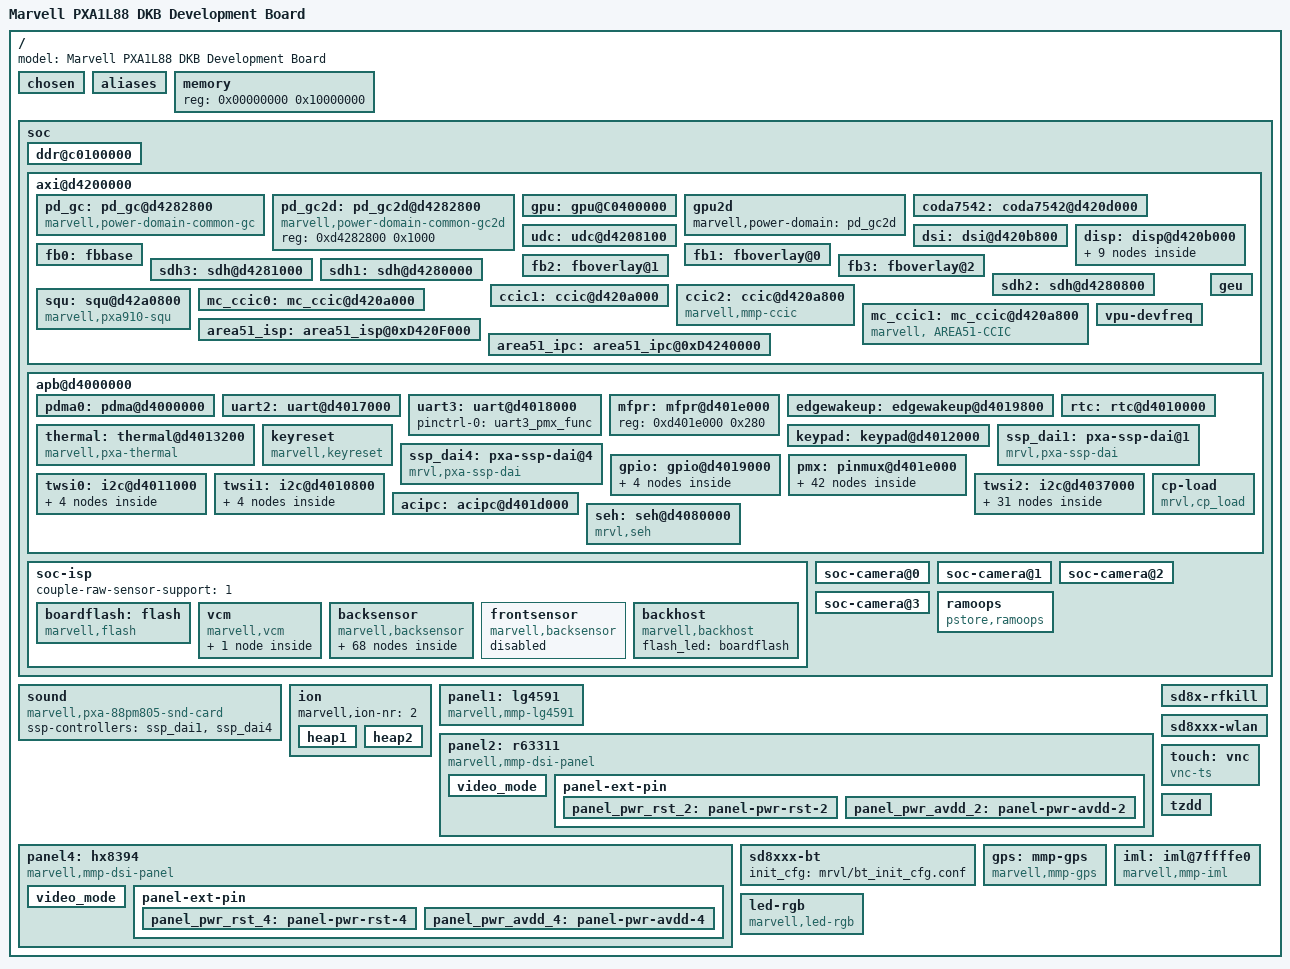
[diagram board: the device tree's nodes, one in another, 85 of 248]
/*
 *  Copyright (C) 2012 Marvell Technology Group Ltd.
 *  Author: Haojian Zhuang <haojian.zhuang@marvell.com>
 *
 *  This program is free software; you can redistribute it and/or modify
 *  it under the terms of the GNU General Public License version 2 as
 *  publishhed by the Free Software Foundation.
 */

/memreserve/ 0x09000000 0x01000000;	/* GPU (16MB)*/
/memreserve/ 0x08100000 0x00040000;	/* ramoops buffer (256KB) */
#include "pxa1088.dtsi"
#include "pxa1L88-pmic-config.dtsi"
#include <dt-bindings/mmc/pxa_sdhci.h>

/ {
	model = "Marvell PXA1L88 DKB Development Board";

	chosen {
		bootargs = "console=ttyS0,115200 root=/dev/nfs nfsroot=192.168.1.100:/nfsroot/ ip=192.168.1.101:192.168.1.100::255.255.255.0::eth0:on";
	};

	aliases {
		mmp-camera1 = &ccic2;
		area51-ccic1 = &mc_ccic1;
	};

	memory {
		reg = <0x00000000 0x10000000>;
	};

	soc {
		ddr@c0100000 {  /* DDR memory controller */
			status = "okay";
		};

		axi@d4200000 {	/* AXI */
			pd_gc: pd_gc@d4282800 {
				compatible = "marvell,power-domain-common-gc";
				reg = <0xd4282800 0x1000>;
				marvell,power-domain-parent = <&pd_gc2d>;
			};
			pd_gc2d: pd_gc2d@d4282800 {
				compatible = "marvell,power-domain-common-gc2d";
				reg = <0xd4282800 0x1000>;
			};
			gpu: gpu@C0400000 {
				marvell,power-domain = <&pd_gc>;
				marvell,gpu-mem-base = <0x09000000>;
				marvell,gpu-mem-size = <0x1000000>;
				status = "okay";
			};

			gpu2d {
				marvell,power-domain = <&pd_gc2d>;
				status = "okay";
			};

			coda7542: coda7542@d420d000 {
				marvell,sram-internal = <1>;
				marvell,nv21_support = <1>;
				status = "okay";
			};

			udc: udc@d4208100 {
				status = "okay";
			};

			dsi: dsi@d420b800 {
				marvell,phy-name = "mmp_dsi1";
				marvell,plat-path-name = "mmp_pnpath";
				marvell,dsi-lanes = <4>;
				marvell,burst-mode = <2>;
				marvell,hbp-en;
				status = "okay";
			};

			disp: disp@d420b000 {
				marvell,disp-name = "disp_name";
				marvell,path-num = <2>;
				marvell,master-path = "mmp_pnpath";
				marvell,slave-path = "mmp_tvpath";
				status = "okay";
				path1 {
					marvell,path-name = "mmp_pnpath";
					marvell,overlay-num = <2>;
					marvell,overlay-table = <0>, <1>;
					marvell,output-type = <1>;
					marvell,path-config = <0x10>;
					marvell,link-config = <0x1>;
					1080p {
						disp1_clksrc = "pll1_416m";
						dsipll_clksrc = "pll1_832m";
						pn_sclk_clksrc = "dsi_pll";
					};
					720p {
						disp1_clksrc = "pll1_416m";
						dsipll_clksrc = "pll3";
						pn_sclk_clksrc = "disp1";
					};
					qhd {
						disp1_clksrc = "pll1_416m";
						dsipll_clksrc = "pll3";
						pn_sclk_clksrc = "disp1";
					};
					WVGA {
						disp1_clksrc = "pll1_416m";
						dsipll_clksrc = "pll3";
						pn_sclk_clksrc = "dsi_pll";
					};
					disp_apmu {
						plat = <1>;
						apmu-reg = <0xd428284c>;
						clksrc-bit = <6>;
						parent1-clk-tbl = "disp1", "dsi_pll";
						parent2-clk-tbl = "pll1_416m", "pll1_624", "pll3", "pll2", "pll1_832m";
					};
				};
				path2 {
					marvell,path-name = "mmp_tvpath";
					marvell,overlay-num = <2>;
					marvell,overlay-table = <2>, <3>;
					marvell,output-type = <1>;
					marvell,path-config = <0x10>;
					marvell,link-config = <0x1>;
					1080p {
						disp1_clksrc = "pll1_416m";
						dsipll_clksrc = "pll1_832m";
						pn_sclk_clksrc = "dsi_pll";
					};
					720p {
						disp1_clksrc = "pll1_416m";
						dsipll_clksrc = "pll3";
						pn_sclk_clksrc = "disp1";
					};
				};
			};

			fb0: fbbase {
				marvell,fb-name = "mmp-fb";
				marvell,path-name = "mmp_pnpath";
				marvell,overlay-id = <1>;
				marvell,default-pixfmt = <0x109>;
				marvell,buffer-num = <3>;
				marvell,fb-mem = <0x17000000>;
				status = "okay";
			};

			fb1: fboverlay@0 {
				marvell,fb-name = "mmp-fb-overlay.0";
				marvell,path-name = "mmp_pnpath";
				marvell,overlay-id = <0>;
				status = "okay";
			};

			fb2: fboverlay@1 {
				marvell,fb-name = "mmp-fb-overlay.1";
				marvell,path-name = "mmp_tvpath";
				marvell,overlay-id = <3>;
				status = "okay";
			};

			fb3: fboverlay@2 {
				marvell,fb-name = "mmp-fb-overlay.2";
				marvell,path-name = "mmp_tvpath";
				marvell,overlay-id = <2>;
				status = "okay";
			};

			/* eMMC */
			sdh3: sdh@d4281000 {
				pinctrl-names = "default";
				pinctrl-0 = <&sdh3_pmx_func1 &sdh3_pmx_func2>;
				bus-width = <8>;
				non-removable;
				marvell,sdh-pm-runtime-en;
				marvell,sdh-quirks = <(
						SDHCI_QUIRK_BROKEN_ADMA |
						SDHCI_QUIRK_BROKEN_CARD_DETECTION
						)>;
				marvell,sdh-quirks2 = <(
						SDHCI_QUIRK2_BUS_CLK_GATE_ENABLED |
						SDHCI_QUIRK2_TIMEOUT_SHORT
						)>;
				marvell,sdh-host-caps = <(MMC_CAP_1_8V_DDR)>;
				marvell,sdh-host-caps2 = <(MMC_CAP2_DISABLE_BLK_ASYNC |
						MMC_CAP2_HS200_1_8V_SDR
						)>;
				marvell,sdh-flags = <(
						PXA_FLAG_SD_8_BIT_CAPABLE_SLOT |
						PXA_FLAG_ENABLE_CLOCK_GATING |
						PXA_FLAG_TX_SEL_BUS_CLK
					      )>;
/* prop "sdh-dtr-data": <timing preset_rate src_rate tx_delay rx_delay rx_clk_sel0 rx_clk_sel1 fclk_tune_level fclk_fix_en> */
				marvell,sdh-dtr-data = <PXA_MMC_TIMING_LEGACY PXA_SDH_DTR_26M PXA_SDH_DTR_104M 0 0 0 0 0 0>,
						<PXA_MMC_TIMING_MMC_HS PXA_SDH_DTR_52M PXA_SDH_DTR_104M 0 0 0 0 0 0>,
						<PXA_MMC_TIMING_UHS_DDR50 PXA_SDH_DTR_52M PXA_SDH_DTR_104M 0x6F 0 0 0 0 0>,
						<PXA_MMC_TIMING_MMC_HS200 PXA_SDH_DTR_208M PXA_SDH_DTR_208M 0 0 0 0 0 0>,
						<PXA_MMC_TIMING_MAX PXA_SDH_DTR_PS_NONE PXA_SDH_DTR_104M 0 0 0 0 0 0>;
				marvell,sdh-tuning-win-limit = <120>;
				marvell,sdh-dvfs-levels = <1 3>; /* tuning from dvfs level 1 to 3  */
				marvell,sdh-tuning-mode = <PXA_SDH_TUNING_DVFS>;

				status = "okay";
			};

			/* SD card */
			sdh1: sdh@d4280000 {
				pinctrl-names = "default";
				pinctrl-0 = <&sdh1_pmx_func1 &sdh1_pmx_func2 &sdh1_pmx_func3 &sdh1_pmx_func4>;
				vqmmc-supply	= <&ldo5>;
				vmmc-supply	= <&ldo4>;
				cd-gpios = <&gpio 91 0>;
				cd-inverted;
				bus-width = <4>;
				wp-inverted;
				marvell,sdh-pm-runtime-en;
				marvell,sdh-host-caps-disable = <(MMC_CAP_UHS_SDR104)>;
				marvell,sdh-quirks = <(
						SDHCI_QUIRK_INVERTED_WRITE_PROTECT |
						SDHCI_QUIRK_BROKEN_CARD_DETECTION
						)>;
				marvell,sdh-quirks2 = <(
						SDHCI_QUIRK2_BUS_CLK_GATE_ENABLED |
						SDHCI_QUIRK2_TIMEOUT_SHORT
						)>;
				marvell,sdh-flags = <(
						PXA_FLAG_TX_SEL_BUS_CLK |
						PXA_FLAG_ENABLE_CLOCK_GATING
					      )>;
/* prop "sdh-dtr-data": <timing preset_rate src_rate tx_delay rx_delay rx_clk_sel0 rx_clk_sel1 fclk_tune_level fclk_fix_en> */
				marvell,sdh-dtr-data = <PXA_MMC_TIMING_LEGACY PXA_SDH_DTR_26M PXA_SDH_DTR_104M 0 0 0 0 0 0>,
						<PXA_MMC_TIMING_SD_HS PXA_SDH_DTR_52M PXA_SDH_DTR_104M 0 0 0 0 0 0>,
						<PXA_MMC_TIMING_UHS_DDR50 PXA_SDH_DTR_52M PXA_SDH_DTR_104M 0 0 0 0 0 0>,
						<PXA_MMC_TIMING_MAX PXA_SDH_DTR_PS_NONE PXA_SDH_DTR_104M 0 0 0 0 0 0>;
				status = "okay";
			};

			/* SDIO */
			sdh2: sdh@d4280800 {
				pinctrl-names = "default", "fast", "sleep";
				pinctrl-0 = <&sdh2_pmx_func1 &sdh2_pmx_func2 &sdh2_pmx_func3 &sdh2_pmx_func4>;
				pinctrl-1 = <&sdh2_pmx_func1_fast &sdh2_pmx_func2_fast &sdh2_pmx_func3 &sdh2_pmx_func4>;
				pinctrl-2 = <&sdh2_pmx_edge_wakeup>;
				bus-width = <4>;
				marvell,sdh-pm-runtime-en;
				marvell,sdh-quirks = <(SDHCI_QUIRK_BROKEN_CARD_DETECTION)>;
				marvell,sdh-quirks2 = <(
						SDHCI_QUIRK2_BUS_CLK_GATE_ENABLED |
						SDHCI_QUIRK2_SDIO_SW_CLK_GATE |
						SDHCI_QUIRK2_HOLDSUSPEND_AFTER_REQUEST |
						SDHCI_QUIRK2_BASE_CLOCK_ALWAYS_ON |
						SDHCI_QUIRK2_MANUAL_CARD_DETECT |
						SDHCI_QUIRK2_TIMEOUT_SHORT
						)>;
				marvell,sdh-pm-caps = <(MMC_PM_KEEP_POWER)>;
				marvell,sdh-host-caps2 = <(MMC_CAP2_NO_VOLTAGE_SWITCH)>;
				marvell,sdh-host-caps-disable = <(
						MMC_CAP_UHS_SDR12 |
						MMC_CAP_UHS_SDR25 |
						MMC_CAP_UHS_SDR50 |
						MMC_CAP_UHS_SDR104
						)>;
				marvell,sdh-flags = <(
						PXA_FLAG_WAKEUP_HOST |
						PXA_FLAG_ENABLE_CLOCK_GATING |
						PXA_FLAG_TX_SEL_BUS_CLK |
						PXA_FLAG_EN_PM_RUNTIME |
						PXA_FLAG_DISABLE_PROBE_CDSCAN
					      )>;
/* prop "sdh-dtr-data": <timing preset_rate src_rate tx_delay rx_delay rx_clk_sel0 rx_clk_sel1 fclk_tune_level fclk_fix_en> */
				marvell,sdh-dtr-data = <PXA_MMC_TIMING_LEGACY PXA_SDH_DTR_26M PXA_SDH_DTR_104M 0 0 0 0 0 0>,
						<PXA_MMC_TIMING_SD_HS PXA_SDH_DTR_45M PXA_SDH_DTR_89M 0 0 0 0 0 0>,
						<PXA_MMC_TIMING_UHS_DDR50 PXA_SDH_DTR_52M PXA_SDH_DTR_104M 0 0 0 0 0 0>,
						<PXA_MMC_TIMING_MAX PXA_SDH_DTR_PS_NONE PXA_SDH_DTR_89M 0 0 0 0 0 0>;
				status = "okay";
			};

			ccic1: ccic@d420a000 {
			   pinctrl-names = "default";
			   pwdn-gpios = <&gpio 80 0>;
			   reset-gpios = <&gpio 67 0>;
			   af_2v8-supply = <&ldo10>;
			   avdd_2v8-supply = <&ldo11>;
			   dovdd_1v8-supply = <&voutsw>;
			   dvdd_1v2-supply = <&ldo12>;
			   status = "okay";
			};

			ccic2: ccic@d420a800 {
			   compatible = "marvell,mmp-ccic";
			   reg = <0xd420a800 0x2ff>, <0xd4282800 0x1ff>;
			   reg-names = "ccic-regs", "apmu-regs";
			   dma-burst = <64>;
			   mclk-src = <3>;
			   mclk-div = <13>;
			   interrupts = <0 77 0x4>;
			   pinctrl-names = "default";
			   pwdn-gpios = <&gpio 68 0>;
			   reset-gpios = <&gpio 69 0>;
			   af_2v8-supply = <&ldo10>;
			   avdd_2v8-supply = <&ldo11>;
			   dovdd_1v8-supply = <&voutsw>;
			   dvdd_1v2-supply = <&ldo12>;
			   status = "okay";
			};

			squ: squ@d42a0800 {
				compatible = "marvell,pxa910-squ";
				reg = <0xd42a0800 0x100>;
				interrupts = <0 46 0x4>;
				#dma-cells = <1>;
				asram = <&sram>;
			};

			mc_ccic0: mc_ccic@d420a000 {
				status = "okay";
			};

			mc_ccic1: mc_ccic@d420a800 {
				compatible = "marvell, AREA51-CCIC";
				fclk-mhz = <416>;
				mclk-mhz = <24>;
				interrupts = <0 77 0x4>;
				status = "okay";
			};

			area51_isp: area51_isp@0xD420F000 {
				mrvl,memory-priority-addr = <0xc0100000 0x800>;
				mrvl,memory-weight-setting-offset = <0x13c>;
				mrvl,memory-weight-setting = <0x00000000 0x05000000>;
				status = "okay";
			};

			area51_ipc: area51_ipc@0xD4240000 {
				status = "okay";
			};

			vpu-devfreq {
				status = "okay";
			};
			geu: geu {
				status = "okay";
			};
		};

		apb@d4000000 {
			pdma0: pdma@d4000000 {
				status = "okay";
			};

			uart2: uart@d4017000 {
				pinctrl-names = "default", "sleep";
				pinctrl-0 = <&uart2_pmx_func1 &uart2_pmx_func2>;
				pinctrl-1 = <&uart2_pmx_func1_sleep &uart2_pmx_func2>;
				edge-wakeup-gpio = <47>; /* GPIO47: UART rx pin */
				status = "okay";
			};

			uart3: uart@d4018000 {
				pinctrl-names = "default";
				pinctrl-0 = <&uart3_pmx_func>;
				status = "okay";
			};

			mfpr: mfpr@d401e000 {
				reg = <0xd401e000 0x280>;
				status = "ok";
			};

			edgewakeup: edgewakeup@d4019800 {
				status = "ok";
			};

			rtc: rtc@d4010000 {
				status = "okay";
			};

			thermal: thermal@d4013200 {
				compatible = "marvell,pxa-thermal";
				reg = <0xd4013200 0x50>;
				interrupts = <0 60 0x4>;
				trigger_levels_count = <4>;
				type = <2>;
				status = "ok";
			};

			keypad: keypad@d4012000 {
				keypad,num-rows = <2>;
				keypad,num-columns = <1>;
				linux,keymap = <0x00000073
						0x01000072>;
				marvell,debounce-interval = <30>;
				pinctrl-names = "default";
				pinctrl-0 = <&keypad_in_func  &keypad_out_func>;
				status = "okay";
			};

			keyreset {
				compatible = "marvell,keyreset";
				keys-down = <0x73 0x72>;
				keyreset-need-panic;
			};

			ssp_dai1: pxa-ssp-dai@1 {
				compatible = "mrvl,pxa-ssp-dai";
				reg = <0x1 0x0>;
				port = <&ssp1>;
				pinctrl-names = "default","ssp";
				pinctrl-0 = <&i2s_gpio>;
				pinctrl-1 = <&i2s_func>;
				ssp-gpio = <&gpio 21 0 &gpio 22 0 &gpio 23 0 &gpio 24 0>;
				dmas = <&squ 1
					&squ 0>;
				dma-names = "rx", "tx";
				asram = <&sram>;
				platform_driver_name = "tdma_platform";
				burst_size = <4>;
				playback_period_bytes = <4096>;
				playback_buffer_bytes = <20480>;
				capture_period_bytes = <4096>;
				capture_buffer_bytes = <20480>;
			};

			ssp_dai4: pxa-ssp-dai@4 {
				compatible = "mrvl,pxa-ssp-dai";
				reg = <0x4 0x0>;
				port = <&ssp4>;
				pinctrl-names = "default","ssp";
				pinctrl-0 = <&gssp_gpio>;
				pinctrl-1 = <&gssp_func>;
				ssp-gpio = <&gpio 25 0 &gpio 26 0 &gpio 27 0 &gpio 28 0>;
				dmas = <&pdma0 6 0
					&pdma0 7 0>;
				dma-names = "rx", "tx";
				platform_driver_name = "pdma_platform";
				burst_size = <8>;
				playback_period_bytes = <4096>;
				playback_buffer_bytes = <131072>;
				capture_period_bytes = <4096>;
				capture_buffer_bytes = <131072>;
			};

			gpio: gpio@d4019000 {
				status = "okay";
				/*
				 * In theorical, some gpios could be routed to
				 * multiple pins. So define the gpio-ranges in
				 * board file, not silicon file.
				 */
				gcb0: gpio@d4019000 {
					/* gpio offset, pin offset, nr pins */
					gpio-ranges = <&pmx 0 55 32>;
				};
				gcb1: gpio@d4019004 {
					gpio-ranges = <&pmx 0 87 23>;
				};
				gcb2: gpio@d4019008 {
					gpio-ranges = <&pmx 3 110 29>;
				};
				gcb3: gpio@d4019100 {
					gpio-ranges = <&pmx 0 139 3  &pmx 28 52 1>;
				};
			};
			pmx: pinmux@d401e000 {
				/* pin base, nr pins & gpio function */
				pinctrl-single,gpio-range = <
					/*
					 * GPIO number is hardcoded for range at here.
					 * In gpio chip, GPIO number is not hardcoded for range.
					 * Since one gpio pin may be routed to multiple pins,
					 * define these gpio range in pxa910-dkb.dts not pxa910.dtsi.
					 */
					&range 55 55 0	/* GPIO0 ~ GPIO54 */
					&range 110 32 0 /* GPIO67 ~ GPIO98 */
					&range 52 1 0	/* GPIO124 */
				>;
				pinctrl-names = "default";
				pinctrl-0 = <&mfp_pins_group_0 &mfp_pins_group_1 &mfp_pins_group_2 &mfp_pins_group_3 &mfp_pins_group_4 &mfp_pins_group_5 &mfp_pins_group_6 &mfp_pins_group_7>;
				/* MFP_LPM_FLOAT */
				mfp_pins_group_0: mfp_pins_group_0 {
					pinctrl-single,pins = <
						DF_IO8 AF0
						DF_IO9 AF0
						DF_IO10 AF0
						DF_IO11 AF0
						DF_IO12 AF0
						DF_IO13 AF0
						DF_IO14 AF0
						DF_IO15 AF0
						DF_WEn AF1
						DF_REn AF1
						DF_ALE_SM_WEn AF1
						DF_RDY0 AF0
					>;
					MFP_LPM_FLOAT;
				};

				/* MFP_PULL_LOW && MFP_LPM_PULL_FLOAT */
				mfp_pins_group_1: mfp_pins_group_1 {
					pinctrl-single,pins = <
						DF_nCS0_SM_nCS2 AF0
						DF_nCS1_SM_nCS3 AF1
						SM_nCS1 AF1
						GPIO15 AF0
						GPIO72 AF0
					>;
					DS_MEDIUM;PULL_DOWN;EDGE_NONE;LPM_FLOAT;
				};

				/* MFP_PULL_LOW && LPM_OUTPUT_DRIVE_LOW */
				mfp_pins_group_2: mfp_pins_group_2 {
					pinctrl-single,pins = <
						GPIO18 AF0
					>;
					DS_MEDIUM;PULL_DOWN;EDGE_NONE;LPM_DRIVE_LOW;
				};

				/* MFP_PULL_LOW */
				mfp_pins_group_3: mfp_pins_group_3 {
					pinctrl-single,pins = <
						GPIO70 AF0
						GPIO97 AF0
						GPIO43 AF0
						GPIO44 AF0
						GPIO49 AF0
						GPIO50 AF0
						GPIO90 AF0
						GPIO92 AF0
						GPIO98 AF0
					>;
					MFP_PULL_DOWN;
				};

				/* MFP_PULL_HIGH */
				mfp_pins_group_4: mfp_pins_group_4 {
					pinctrl-single,pins = <
						SM_RDY_GPIO_3 AF1
						GPIO14 AF0
						GPIO91 AF0
					>;
					MFP_PULL_UP;
				};

				/* MFP_PULL_FLOAT */
				mfp_pins_group_5: mfp_pins_group_5 {
					pinctrl-single,pins = <
						GPIO4 AF0
						GPIO20 AF0
						GPIO36 AF0
						GPIO96 AF0
						GPIO67 AF0
						GPIO68 AF0
						GPIO69 AF0
						GPIO80 AF0
					>;
					MFP_PULL_FLOAT;
				};

				/* MFP_PULL_FLOAT && MFP_LPM_PULL_FLOAT */
				mfp_pins_group_6: mfp_pins_group_6 {
					pinctrl-single,pins = <
						GPIO32 AF0
						GPIO12 AF0
					>;
					DS_MEDIUM;PULL_FLOAT;EDGE_NONE;LPM_FLOAT;
				};

				/* MFP_DEFAULT */
				mfp_pins_group_7: mfp_pins_group_7 {
					pinctrl-single,pins = <
						GPIO124 AF0
						GPIO3 AF0
						GPIO5 AF0
						GPIO6 AF0
						GPIO11 AF0
						GPIO13 AF0
						GPIO19 AF0
						GPIO10 AF0
						GPIO30 AF0
						GPIO31 AF0
						GPIO33 AF0
						GPIO34 AF0
						GPIO35 AF0
						GPIO51 AF1
						GPIO52 AF1
						GPIO73 AF0
						GPIO74 AF0
						GPIO75 AF0
						GPIO76 AF0
						GPIO77 AF1
						GPIO78 AF0
						GPIO79 AF0
					>;
					MFP_DEFAULT;
				};

				/* MFP_PULL_LOW | MFP_LPM_FLOAT */
				sdh1_pmx_func1: sdh1_pmx_func1 {
					pinctrl-single,pins = <
						MMC1_DAT7 AF0
						MMC1_DAT6 AF0
						MMC1_DAT5 AF0
						MMC1_DAT4 AF0
						MMC1_WP AF0
					>;
					DS_MEDIUM;PULL_DOWN;EDGE_NONE;LPM_FLOAT;
				};

				/* no pull, no LPM */
				sdh1_pmx_func2: sdh1_pmx_func2 {
					pinctrl-single,pins = <
						MMC1_DAT3 AF0
						MMC1_DAT2 AF0
						MMC1_DAT1 AF0
						MMC1_DAT0 AF0
						MMC1_CMD AF0
					>;
					MFP_DEFAULT;
				};

				/* MFP_LPM_DRIVE_LOW */
				sdh1_pmx_func3: sdh1_pmx_func3 {
					pinctrl-single,pins = <
						MMC1_CLK AF0
					>;
					MFP_LPM_DRIVE_LOW;
				};

				/* MFP_PULL_HIGH */
				sdh1_pmx_func4: sdh1_pmx_func4 {
					pinctrl-single,pins = <
						MMC1_CD AF0
					>;
					DS_MEDIUM;PULL_UP;EDGE_NONE;LPM_NONE;
				};

				sdh2_pmx_func1_fast: sdh2_pmx_func1_fast {
						pinctrl-single,pins = <
							GPIO37 AF1
							GPIO38 AF1
							GPIO39 AF1
							GPIO40 AF1
							GPIO41 AF1
						>;
						DS_FAST;PULL_NONE;EDGE_NONE;LPM_NONE;
				};

				sdh2_pmx_func2_fast: sdh2_pmx_func2_fast {
						pinctrl-single,pins = <
							GPIO42 AF1
						>;
						DS_FAST;PULL_NONE;EDGE_NONE;LPM_DRIVE_LOW;
				};

				sdh2_pmx_func1: sdh2_pmx_func1 {
						pinctrl-single,pins = <
							GPIO37 AF1
							GPIO38 AF1
							GPIO39 AF1
							GPIO40 AF1
							GPIO41 AF1
						>;
						MFP_DEFAULT;
				};

				sdh2_pmx_func2: sdh2_pmx_func2 {
						pinctrl-single,pins = <
							GPIO42 AF1
						>;
						DS_SLOW0;PULL_NONE;EDGE_NONE;LPM_DRIVE_LOW;
				};

				sdh2_pmx_func3: sdh2_pmx_func3 {
						pinctrl-single,pins = <
							GPIO7 AF0
							GPIO71 AF0
						>;
						DS_MEDIUM;PULL_FLOAT;EDGE_NONE;LPM_NONE;
				};

				sdh2_pmx_func4: sdh2_pmx_func4 {
						pinctrl-single,pins = <
							GPIO8 AF0
							GPIO9 AF0
						>;
						DS_MEDIUM;PULL_DOWN;EDGE_NONE;LPM_NONE;
				};

				sdh2_pmx_edge_wakeup: sdh2_pmx_edge_wakeup {
						pinctrl-single,pins = <
							GPIO39 AF1
						>;
						DS_MEDIUM;PULL_NONE;EDGE_BOTH;LPM_NONE;
				};

				/* no pull, no LPM */
				sdh3_pmx_func1: sdh3_pmx_func1 {
					pinctrl-single,pins = <
						ND_IO7 AF1
						ND_IO6 AF1
						ND_IO5 AF1
						ND_IO4 AF1
						ND_IO3 AF1
						ND_IO2 AF1
						ND_IO1 AF1
						ND_IO0 AF1
						ND_CLE_SM_OEN AF1
						SM_BEN0 AF2
					>;
					MFP_DEFAULT;
				};

				/* MFP_LPM_DRIVE_LOW */
				sdh3_pmx_func2: sdh3_pmx_func2 {
					pinctrl-single,pins = <
						SM_SCLK AF1
					>;
					MFP_LPM_DRIVE_LOW;
				};

				uart2_pmx_func1: uart2_pmx_func1 {
					pinctrl-single,pins = <
						GPIO47 AF6
					>;
					MFP_DEFAULT;
				};

				uart2_pmx_func2: uart2_pmx_func2 {
					pinctrl-single,pins = <
						GPIO48 AF6
					>;
					MFP_DEFAULT;
				};

				uart2_pmx_func1_sleep: uart2_pmx_func1_sleep {
					pinctrl-single,pins = <
						GPIO47 AF6
					>;
					DS_MEDIUM;PULL_NONE;EDGE_BOTH;LPM_NONE;
				};

				uart3_pmx_func: uart3_pmx_func {
					pinctrl-single,pins = <
						GPIO45 AF1
						GPIO46 AF1
					>;
					MFP_DEFAULT;
				};

				keypad_in_func: keypad_in_func {
					pinctrl-single,pins = <
						GPIO0 AF1
						GPIO2 AF1
					>;
					MFP_DEFAULT;
				};

				keypad_out_func: keypad_out_func {
					pinctrl-single,pins = <
						GPIO1 AF1
					>;
					DS_MEDIUM;PULL_FLOAT;EDGE_NONE;LPM_DRIVE_HIGH;
				};

				twsi0_pmx_func: twsi0_pmx_func {
					pinctrl-single,pins = <
						GPIO53 AF2
						GPIO54 AF2
					>;
					MFP_LPM_FLOAT;
				};
				twsi0_pmx_gpio: twsi0_pmx_gpio {
					pinctrl-single,pins = <
						GPIO53 AF0
						GPIO54 AF0
					>;
					MFP_LPM_FLOAT;
				};
				twsi1_pmx_func: twsi1_pmx_func {
					pinctrl-single,pins = <
						GPIO87 AF5
						GPIO88 AF5
					>;
					MFP_LPM_FLOAT;
				};
				twsi1_pmx_gpio: twsi1_pmx_gpio {
					pinctrl-single,pins = <
						GPIO87 AF0
						GPIO88 AF0
					>;
					MFP_LPM_FLOAT;
				};
				pm830_pmx_func1: pm830_pmx_func1 {
					pinctrl-single,pins = <
						GPIO29 AF0
					>;
					MFP_DEFAULT;
				};
				pm830_pmx_func1_sleep: pm830_pmx_func1_sleep {
					pinctrl-single,pins = <
						GPIO29 AF0
					>;
					DS_MEDIUM;PULL_NONE;EDGE_BOTH;LPM_NONE;
				};
				touch_pins: touch_pins {
					pinctrl-single,pins = <
						GPIO16 AF0
						GPIO17 AF0
					>;
					MFP_LPM_FLOAT;
				};
				i2s_func: i2s_func {
					pinctrl-single,pins = <
						GPIO21 AF1
						GPIO22 AF1
						GPIO23 AF1
						GPIO24 AF1
					>;
					MFP_DEFAULT;
				};
				i2s_gpio: i2s_gpio {
					pinctrl-single,pins = <
						GPIO21 AF0
						GPIO22 AF0
						GPIO23 AF0
						GPIO24 AF0
					>;
					MFP_LPM_FLOAT;
				};
				/* no pull, no LPM */
				dvc_pmx_func: dvc_pmx_func {
					pinctrl-single,pins = <
						GPIO93 AF5
						GPIO94 AF5
					>;
					MFP_DEFAULT;
				};
				gssp_func: gssp_func {
					pinctrl-single,pins = <
						GPIO25 AF1
						GPIO26 AF1
						GPIO27 AF1
						GPIO28 AF1
				>;
					MFP_DEFAULT;
				};
				gssp_gpio: gssp_gpio {
					pinctrl-single,pins = <
						GPIO25 AF0
						GPIO26 AF0
						GPIO27 AF0
						GPIO28 AF0
					>;
					MFP_LPM_FLOAT;
				};
				gps_pmx_eclk: gps_pmx_eclk {
					/* eclk */
					pinctrl-single,pins = <
						GPIO89 AF5
					>;
					MFP_DEFAULT;
				};
				gps_pmx_gpio: gps_pmx_gpio {
					/* gpio */
					pinctrl-single,pins = <
						GPIO89 AF0
					>;
					MFP_DEFAULT;
				};
				led_pmx_func: led_pmx_func {
					pinctrl-single,pins = <
						/* LED_R_CTRL */
						SM_BE1 AF0
						/* LED_G_CTRL */
						SM_nCS0 AF1
						/* LED_B_CTRL */
						SM_ADVMUX AF1
					>;
					DS_MEDIUM;PULL_FLOAT;EDGE_NONE;LPM_FLOAT;
				};
			};

			twsi0: i2c@d4011000 {
				pinctrl-names = "default","gpio";
				pinctrl-0 = <&twsi0_pmx_func>;
				pinctrl-1 = <&twsi0_pmx_gpio>;
				i2c-gpio = <&gpio 53 0 &gpio 54 0>;
				status = "okay";

				touch1: s3202@720p {
					compatible = "synaptics,s3202-touch";
					pinctrl-names = "default"; pinctrl-0 = <&touch_pins>;
					reg = <0x22>;
					interrupt-parent = <&gpio>;
					interrupts = <17 0x1>;
					/* IRQF_ONESHOT | IRQF_TRIGGER_FALLING */
					synaptics,irq-flags =  <0x2002>;
					synaptics,irq-gpios = <&gpio 17 0>;
					synaptics,reset-gpios = <&gpio 16 0>;
					synaptics,sensor_res_x = <720>;
					synaptics,sensor_res_y = <1280>;
					synaptics,sensor_max_x = <798>;
					synaptics,sensor_max_y = <1392>;
					synaptics,sensor_margin_x = <39>;
					synaptics,sensor_margin_y = <0>;
					avdd-supply = <&ldo10>;
				};

				touch2: s3202@1080p {
					compatible = "synaptics,s3202-touch";
					pinctrl-names = "default"; pinctrl-0 = <&touch_pins>;
					reg = <0x22>;
					interrupt-parent = <&gpio>;
					interrupts = <17 0x1>;
					/* IRQF_ONESHOT | IRQF_TRIGGER_FALLING */
					synaptics,irq-flags =  <0x2002>;
					synaptics,irq-gpios = <&gpio 17 0>;
					synaptics,reset-gpios = <&gpio 16 0>;
					synaptics,sensor_res_x = <1080>;
					synaptics,sensor_res_y = <1920>;
					synaptics,sensor_max_x = <1080>;
					synaptics,sensor_max_y = <2070>;
					synaptics,sensor_margin_x = <0>;
					synaptics,sensor_margin_y = <0>;
					avdd-supply = <&ldo10>;
				};

				touch3: gt913@720p {
					compatible = "goodix,gt913-touch";
					pinctrl-names = "default"; pinctrl-0 = <&touch_pins>;
					reg = <0x5d>;
					interrupt-parent = <&gpio>;
					interrupts = <17 0x1>;
					irq-gpios = <&gpio 17 0>;
					reset-gpios = <&gpio 16 0>;
					goodix,cfg-group = <0>;
					goodix,max-height = <1280>;
					goodix,max-width = <720>;
					avdd-supply = <&ldo10>;
				};

				touch4: gt913@1080p {
					compatible = "goodix,gt913-touch";
					pinctrl-names = "default"; pinctrl-0 = <&touch_pins>;
					reg = <0x5d>;
					interrupt-parent = <&gpio>;
					interrupts = <17 0x1>;
					irq-gpios = <&gpio 17 0>;
					reset-gpios = <&gpio 16 0>;
					goodix,cfg-group = <0>;
					goodix,max-height = <1920>;
					goodix,max-width = <1080>;
					avdd-supply = <&ldo10>;
				};
			};

			twsi1: i2c@d4010800 {
				pinctrl-names = "default","gpio";
				pinctrl-0 = <&twsi1_pmx_func>;
				pinctrl-1 = <&twsi1_pmx_gpio>;
				i2c-gpio = <&gpio 87 0 &gpio 88 0>;
				status = "okay";

					sensor1: isl29043@44 {
					compatible = "intersil,isl29043";
					reg = <0x44>;
					interrupt-parent = <&gpio>;
					interrupts = <14 0x1>;
					irq-gpios = <&gpio 14 0>;
					intersil,wakup-gpios = <&gpio 14 0>;
					avdd-supply = <&ldo10>;
				};
					sensor2: bmp18x@77 {
					compatible = "BOSCH,bmp18x";
					reg = <0x77>;
					avdd-supply = <&ldo10>;
				};
					sensor3: mpu9250@69 {
					compatible = "invensense,mpu9250";
					reg = <0x69>;
					interrupt-parent = <&gpio>;
					interrupts = <92 0x2>;
					inven,irq-gpios = <&gpio 92 0x00>;
					avdd-supply = <&ldo10>;
					axis_map_x = <0>;
					negate_x = <0>;
					axis_map_y = <4>;
					negate_y = <0>;
					axis_map_z = <8>;
					negate_z = <0>;
					inven,secondary_axis_map_x = <0>;
					inven,secondary_negate_x = <0>;
					inven,secondary_axis_map_y = <4>;
					inven,secondary_negate_y = <0>;
					inven,secondary_axis_map_z = <8>;
					inven,secondary_negate_z = <0>;
					inven,secondary_type = "compass";
					inven,secondary_name = "ak8963";
					inven,secondary_reg = <0xc>;
				};
					sensor4: apds9930@39 {
					compatible = "avago,apds9930";
					reg = <0x39>;
					interrupt-parent = <&gpio>;
					interrupts = <14 0x1>;
					irq-gpios = <&gpio 14 0>;
					avdd-supply = <&ldo10>;
				};

			};

			twsi2: i2c@d4037000 {
				status = "okay";

				pmic1: 88pm822@30 {
					compatible = "marvell,88pm800";
					reg = <0x30>;
					interrupts = <0 4 0x4>;
					interrupt-parent = <&gic>;
					interrupt-controller;
					#interrupt-cells = <1>;
					marvell,88pm800-irq-write-clear;

					marvell,88pm800-power-page-addr = <0x31>;
					marvell,88pm800-gpadc-page-addr = <0x32>;

					regulators {
						compatible = "marvell,88pm80x-regulator";

						BUCK1 {
							regulator-compatible = "88PM800-BUCK1";
							regulator-min-microvolt = <600000>;
							regulator-max-microvolt = <1800000>;
							regulator-boot-on;
							regulator-always-on;
						};
						BUCK2 {
							regulator-compatible = "88PM800-BUCK2";
							regulator-min-microvolt = <600000>;
							regulator-max-microvolt = <3300000>;
							regulator-boot-on;
							regulator-always-on;
						};
						BUCK3 {
							regulator-compatible = "88PM800-BUCK3";
							regulator-min-microvolt = <600000>;
							regulator-max-microvolt = <3300000>;
							regulator-boot-on;
							regulator-always-on;
						};
						BUCK4 {
							regulator-compatible = "88PM800-BUCK4";
							regulator-min-microvolt = <600000>;
							regulator-max-microvolt = <3300000>;
							regulator-boot-on;
							regulator-always-on;
						};
						BUCK5 {
							regulator-compatible = "88PM800-BUCK5";
							regulator-min-microvolt = <600000>;
							regulator-max-microvolt = <3950000>;
							regulator-boot-on;
							regulator-always-on;
						};
						LDO1 {
							regulator-compatible = "88PM800-LDO1";
							regulator-min-microvolt = <1700000>;
							regulator-max-microvolt = <3300000>;
							regulator-boot-on;
							regulator-always-on;
						};
						LDO2 {
							regulator-compatible = "88PM800-LDO2";
							regulator-min-microvolt = <1700000>;
							regulator-max-microvolt = <3300000>;
							regulator-boot-on;
							regulator-always-on;
						};
						LDO3 {
							regulator-compatible = "88PM800-LDO3";
							regulator-min-microvolt = <1200000>;
							regulator-max-microvolt = <3300000>;
							regulator-boot-on;
							regulator-always-on;
						};
						ldo4: LDO4 {
							regulator-compatible = "88PM800-LDO4";
							regulator-min-microvolt = <1200000>;
							regulator-max-microvolt = <3300000>;
						};
						ldo5: LDO5 {
							regulator-compatible = "88PM800-LDO5";
							regulator-min-microvolt = <1200000>;
							regulator-max-microvolt = <3300000>;
						};
						LDO6 {
							regulator-compatible = "88PM800-LDO6";
							regulator-min-microvolt = <1200000>;
							regulator-max-microvolt = <3300000>;
						};
						LDO7 {
							regulator-compatible = "88PM800-LDO7";
							regulator-min-microvolt = <1200000>;
							regulator-max-microvolt = <3300000>;
							regulator-boot-on;
							regulator-always-on;
						};
						ldo8: LDO8 {
							regulator-compatible = "88PM800-LDO8";
							regulator-min-microvolt = <1200000>;
							regulator-max-microvolt = <3300000>;
							regulator-boot-on;
							regulator-always-on;
						};
						ldo9: LDO9 {
							regulator-compatible = "88PM800-LDO9";
							regulator-min-microvolt = <1200000>;
							regulator-max-microvolt = <3300000>;
						};
						ldo10: LDO10 {
							regulator-compatible = "88PM800-LDO10";
							regulator-min-microvolt = <1200000>;
							regulator-max-microvolt = <3300000>;
							regulator-boot-on;
						};
						ldo11: LDO11 {
							regulator-compatible = "88PM800-LDO11";
							regulator-min-microvolt = <1200000>;
							regulator-max-microvolt = <3300000>;
							regulator-boot-on;
						};
						ldo12: LDO12 {
							regulator-compatible = "88PM800-LDO12";
							regulator-min-microvolt = <600000>;
							regulator-max-microvolt = <1500000>;
							regulator-boot-on;
							regulator-always-on;
						};
						ldo13: LDO13 {
							regulator-compatible = "88PM800-LDO13";
							regulator-min-microvolt = <1700000>;
							regulator-max-microvolt = <3300000>;
							regulator-boot-on;
						};
						ldo14: LDO14 {
							regulator-compatible = "88PM800-LDO14";
							regulator-min-microvolt = <1700000>;
							regulator-max-microvolt = <2800000>;
						};
						voutsw: VOUTSW {
							regulator-compatible = "88PM800-VOUTSW";
							regulator-min-microvolt = <1700000>;
							regulator-max-microvolt = <1800000>;
						};
					};

					vibrator: vibrator {
						compatible = "marvell,88pm80x-vibrator";
						min-timeout = <10>;
						duty-cycle = <0x3f>;
					};

					headset {
						compatible = "marvell,88pm80x-headset";
						marvell,switch-name = "h2w";
						marvell,headset-flag = <1>;
						marvell,hook-press-th = <60>;
						marvell,vol-up-press-th = <250>;
						marvell,vol-down-press-th = <500>;
						marvell,mic-det-th = <600>;
						marvell,press-release-th = <600>;
						marvell,micbias-supply = <&ldo14>;
					};

					dvc {
						compatible = "marvell,88pm8xx-dvc";
						/* pm822 dvc affect buck1/3/5, affected 32bit = (1 << 4) | (1 << 2) | (1 << 0)*/
						dvc-affected-buckbits = <21>;
						pinctrl-names = "default";
						pinctrl-0 = <&dvc_pmx_func>;
					};

					battery {
						compatible = "marvell,88pm80x-battery";
						sw-fg-use-ntc;
						full-capacity = <1500>; /* mAh */
						r1-resistor = <40>; /* mohm */
						r2-resistor = <30>; /* mohm */
						rs-resistor = <120>; /* mohm */
						roff-resistor = <60>; /* mohm */
						roff-initial-resistor = <60>; /* mohm */

						online-gpadc = <1>;
						temperature-gpadc = <2>;

						times-in-zero-degree = <1>;
						offset-in-zero-degree = <0>;

						times-in-ten-degree = <2>;
						offset-in-ten-degree = <100>;

						power-off-threshold = <3350>; /* mV */
						safe-power-off-threshold = <3000>; /* mV */

						online-gp-bias-curr = <76>; /* uA */
						hi-volt-online = <250>;	/* mV */
						lo-volt-online = <120>; /* mV */
						hi-volt-temp = <1250>; /* mV */
						lo-volt-temp = <300>; /* mV */


						soc-ramp-up-interval = <150>; /* s */
						need-offset-trim;
					};
			       };

				pmic2: 88pm805@38 {
					compatible = "marvell,88pm805";
					reg = <0x38>;
					interrupt-parent = <&gpio>;
					interrupts = <124 0x1>;
					marvell,88pm805-irq-write-clear;
				};

				pmic3: 88pm830@68 {
					compatible = "marvell,88pm830";

					pinctrl-names = "default", "sleep";
					pinctrl-0 = <&pm830_pmx_func1>;
					pinctrl-1 = <&pm830_pmx_func1_sleep>;
					edge-wakeup-gpio = <29>; /* GPIO29: interrupt line */

					reg = <0x68>;
					interrupt-parent = <&gpio>;
					interrupt-controller;
					/* edge falling */
					interrupts = <29 2>;
					#interrupt-cells = <1>;

					/* IRQF_ONESHOT | IRQF_TRIGGER_FALLING */
					marvell,88pm830-irq-flags =  <0x2002>;

					/*
					 * charger, batttery parameters are based on Lenovo BL209 battery
					 * Part Name: Li-ion Polymer Rechargeable Battery
					 * Pack Parts No.: ALE455557SA
					 * Pack Standard: 2000mAh(0.2C)
					 * Cell Model: SP455557SA
					 * Pack Model: 1S1P-SP455557SA-PCM
					 */
					charger {
						compatible = "marvell,88pm830-chg";
						prechg-current = <100>;	/* mA */
						prechg-voltage = <3300>; /* mV */
						prechg-timeout = <32>; /* minute */

						fastchg-eoc = <20>; /* mA */
						fastchg-voltage = <4200 4200 4000>; /* mV for STR, LTR, HTR */
						fastchg-current = <1500 1000 1500>; /* mA for STR, LTR, HTR*/
						fastchg-timeout = <8>; /* hour */

						over-voltage = <4500>; /* mV */

						no-thermal-support = <1>;
						thermal-threshold = <0x54 0x36 0x14 0xe>;

						temp-configure = <0x22>;
						temp-threshold = <150>;

						mppt-weight = <0x2>; /* 25% */
						mppt-period = <0x7>; /* 20ms */
						mppt-start-current = <0xf>; /* 1600mA */

					};

					battery {
						compatible = "marvell,88pm830-bat";

						marvell,fg-has-external-storage;
						external-storage = <&pmic1>;

						bat-ntc-support = <1>;
						bat-capacity = <2000>;	/* mAh */
						external-resistor = <200>; /* mohm */
						sleep-period = <1000>; /* second */
						supp-threshold = <95>; /* % */
						low-threshold = <30>; /* % */
						high-threshold = <50>; /* % */
						ocv-table = <
							3397 3445 3477 3496 3506 3513 3519 3526 3532 3540
							3551 3563 3576 3587 3600 3612 3625 3637 3649 3662
							3674 3687 3699 3709 3719 3727 3733 3739 3744 3748
							3752 3755 3758 3761 3763 3765 3766 3767 3769 3770
							3771 3772 3773 3774 3776 3777 3778 3780 3781 3784
							3786 3790 3794 3799 3805 3812 3819 3828 3838 3846
							3854 3860 3867 3873 3879 3885 3891 3897 3903 3910
							3916 3923 3930 3937 3944 3951 3959 3966 3973 3981
							3989 3997 4006 4015 4024 4034 4043 4053 4063 4073
							4082 4092 4102 4112 4122 4133 4144 4155 4167 4179
						>;
						power-off-threshold = <3350>; /* mV */
						safe-power-off-threshold = <3000>; /* mV */

						/* battery temerature feature parameters */
						temp-range-num = <2>;
						switch-thr = <15 64>; /* C */
						gp0-bias-curr = <16 56 56>; /* uA */
						/* choose -20C, 0C, 10C, 45C, 50C, 60C as threshold */
						r-tbat-thr = <77523 28704 18410 4847 4101 2981>; /* ohm */
						ntc-table-size = <88>;
						/* -24C, -23C, ..., 62C, 63C */
						ntc-table = <
							96391 91222 86369 81809 77523 73492 69701 66132
							62772 59606 56623 53810 51157 48654 46290 44058
							41950 39957 38072 36290 34603 33006 31494 30062
							28704 27417 26197 25039 23940 22897 21906 20964
							20070 19219 18410 17641 16909 16212 15548 14916
							14313 13739 13192 12670 12171 11696 11242 10809
							10395 10000 9622  9261  8916  8585  8269  7967
							7678  7400  7135  6881  6637  6403  6180  5965
							5759  5561  5372  5189  5015  4847  4686  4531
							4382  4238  4101  3969  3842  3719  3601  3488
							3379  3274  3172  3075  2981  2890  2803  2719
						>;
					};

					led {
						compatible = "marvell,88pm830-led";

						flash-en-gpio = <18>;
						flash-txmsk-gpio = <19>;
						max-flash-current = <1000>; /* mA */
						max-torch-current = <400>; /* mA */
					};
				};
			};

			acipc: acipc@d401d000 {
				status = "okay";
			};

			seh: seh@d4080000 {
				compatible = "mrvl,seh";
				reg = <0xd4080000 0x100>, <0xd403d300 0x4>;
				interrupts = <0 32 0x4>;
				interrupt-names = "CP_TIMER2_3";
				watchdog-type = <1>; /* soc timer */
				timer-num = <2>; /* timer num */
				match-num = <0>; /* match num */
				status = "okay";
			};

			cp-load {
				compatible = "mrvl,cp_load";
				cp-type = <1>; /* pxa1L88 */
				lpm-qos = <PM_QOS_CPUIDLE_BLOCK_AXI>;
				status = "okay";
			};
		};

		soc-isp {
			couple-raw-sensor-support = <1>;
			status = "okay";
			boardflash: flash {
				compatible = "marvell,flash";
				status = "okay";
				pwm_id = <3>;
				lth_brightness = <50>;
				pwm_period_ns = <2000000>;
				flash-gpios = <&gpio 18 0>;
				torcht-gpios = <&gpio 12 0>;
			};
			vcm {
				#address-cells = <1>;
				#size-cells = <0>;
				compatible = "marvell,vcm";
				status = "okay";
				dw9714l: vcm@1 {
					compatible = "marvell,vcm-dw9714l";
					status = "okay";
					vcm-name = "dw9714l";
					reg = <0x0c>;
					af_2v8-supply = <&ldo10>;
				};
			};
			backsensor {
				#address-cells = <1>;
				#size-cells = <0>;
				compatible = "marvell,backsensor";
				status = "okay";
				LSI3H7: sensor@1 {
					compatible = "SSG,lsi3h7","marvell,sensor";
					sensor-name = "lsi3h7";
					reg = <0x10>;
					adapter = <0>;
					type = <1>;
					interface = <0>;
					af_2v8-supply = <&ldo10>;
					avdd_2v8-supply = <&ldo11>;
					dovdd_1v8-supply = <&voutsw>;
					dvdd_1v2-supply = <&ldo12>;
					vcm-subdev = <&dw9714l>;
					status = "okay";
					sensor_power {
						pinctrl-names = "default";
						pwdn-gpios = <&gpio 80 0>;
						reset-gpios = <&gpio 67 0>;
						pwdn-validvalue = <0>;
						reset-validvalue = <0>;
					};
					sensor_id {
						pid_addr = <0x0000 0x0001>;
						pid_value = <0x30 0x87>;
					};
					torch_flash {
						flash-gpios = <&gpio 18 0>;
						torcht-gpios = <&gpio 12 0>;
					};
				};
				ov8858: sensor@2 {
					compatible = "OVT,ov8858","marvell,sensor";
					sensor-name = "ov8858";
					reg = <0x36>;
					adapter = <0>;
					type = <1>;
					interface = <0>;
					af_2v8-supply = <&ldo10>;
					avdd_2v8-supply = <&ldo11>;
					dovdd_1v8-supply = <&voutsw>;
					dvdd_1v2-supply = <&ldo12>;
					vcm-subdev = <&dw9714l>;
					status = "okay";
					sensor_power {
						pinctrl-names = "default";
						pwdn-gpios = <&gpio 80 0>;
						reset-gpios = <&gpio 67 0>;
						pwdn-validvalue = <0>;
						reset-validvalue = <0>;
					};
					sensor_id {
						pid_addr = <0x300b 0x300c>;
						pid_value = <0x88 0x58>;
					};
					torch_flash {
						flash-gpios = <&gpio 18 0>;
						torcht-gpios = <&gpio 12 0>;
					};
				};
				OV8825: sensor@3 {
					compatible = "OVT,ov8825","marvell,sensor";
					sensor-name = "ov8825";
					reg = <0x36>;
					adapter = <0>;
					type = <1>;
					interface = <0>;
					af_2v8-supply = <&ldo10>;
					avdd_2v8-supply = <&ldo11>;
					dovdd_1v8-supply = <&voutsw>;
					dvdd_1v2-supply = <&ldo12>;
					vcm-subdev = <&dw9714l>;
					status = "okay";
					sensor_power {
						pinctrl-names = "default";
						pwdn-gpios = <&gpio 80 0>;
						reset-gpios = <&gpio 67 0>;
						pwdn-validvalue = <0>;
						reset-validvalue = <0>;
					};
					sensor_id {
						pid_addr = <0x300a 0x300b>;
						pid_value = <0x88 0x25>;
					};
					torch_flash {
						flash-gpios = <&gpio 18 0>;
						torcht-gpios = <&gpio 12 0>;
					};
				};
				OV8865: sensor@4 {
					compatible = "OVT,ov8865","marvell,sensor";
					sensor-name = "ov8865";
					reg = <0x10>;
					adapter = <0>;
					type = <1>;
					interface = <0>;
					af_2v8-supply = <&ldo10>;
					avdd_2v8-supply = <&ldo11>;
					dovdd_1v8-supply = <&voutsw>;
					dvdd_1v2-supply = <&ldo12>;
					vcm-subdev = <&dw9714l>;
					status = "okay";
					sensor_power {
						pinctrl-names = "default";
						pwdn-gpios = <&gpio 80 0>;
						reset-gpios = <&gpio 67 0>;
						pwdn-validvalue = <0>;
						reset-validvalue = <0>;
					};
					sensor_id {
						pid_addr = <0x300a 0x300b>;
						pid_value = <0x88 0x65>;
					};
					torch_flash {
						flash-gpios = <&gpio 18 0>;
						torcht-gpios = <&gpio 12 0>;
					};
				};
				OV9760: sensor@5 {
					compatible = "OVT,ov9760","marvell,sensor";
					sensor-name = "ov9760";
					reg = <0x10>;
					adapter = <0>;
					type = <1>;
					interface = <0>;
					af_2v8-supply = <&ldo10>;
					avdd_2v8-supply = <&ldo11>;
					dovdd_1v8-supply = <&voutsw>;
					dvdd_1v2-supply = <&ldo12>;
					status = "okay";
					sensor_power {
						pinctrl-names = "default";
						pwdn-gpios = <&gpio 80 0>;
						reset-gpios = <&gpio 67 0>;
						pwdn-validvalue = <0>;
						reset-validvalue = <0>;
					};
					sensor_id {
						pid_addr = <0x300a 0x300b>;
						pid_value = <0x97 0x60>;
					};
					torch_flash {
						flash-gpios = <&gpio 18 0>;
						torcht-gpios = <&gpio 12 0>;
					};
				};
				GC2235: sensor@6 {
					compatible = "GALAXY,gc2235","marvell,sensor";
					sensor-name = "gc2235";
					reg = <0x10>;
					adapter = <0>;
					type = <0>;
					interface = <0>;
					af_2v8-supply = <&ldo10>;
					avdd_2v8-supply = <&ldo11>;
					dovdd_1v8-supply = <&voutsw>;
					dvdd_1v2-supply = <&ldo12>;
					status = "okay";
					sensor_power {
						pinctrl-names = "default";
						pwdn-gpios = <&gpio 80 0>;
						reset-gpios = <&gpio 67 0>;
						pwdn-validvalue = <1>;
						reset-validvalue = <0>;
					};
					sensor_id {
						pid_addr = <0xf0 0xf1>;
						pid_value = <0x22 0x35>;
					};
					torch_flash {
						flash-gpios = <&gpio 18 0>;
						torcht-gpios = <&gpio 12 0>;
					};
				};
				OV5648: sensor@7 {
					compatible = "OVT,ov5648","marvell,sensor";
					sensor-name = "ov5648";
					reg = <0x36>;
					adapter = <0>;
					type = <1>;
					interface = <0>;
					af_2v8-supply = <&ldo10>;
					avdd_2v8-supply = <&ldo11>;
					dovdd_1v8-supply = <&voutsw>;
					dvdd_1v2-supply = <&ldo12>;
					vcm-subdev = <&dw9714l>;
					status = "okay";
					sensor_power {
						pinctrl-names = "default";
						pwdn-gpios = <&gpio 80 0>;
						reset-gpios = <&gpio 67 0>;
						pwdn-validvalue = <0>;
						reset-validvalue = <0>;
					};
					sensor_id {
						pid_addr = <0x300a 0x300b>;
						pid_value = <0x56 0x48>;
					};
					torch_flash {
						flash-gpios = <&gpio 18 0>;
						torcht-gpios = <&gpio 12 0>;
					};
				};
				ov8850: sensor@8 {
					compatible = "OVT,ov8850","marvell,sensor";
					sensor-name = "ov8850";
					reg = <0x36>;
					adapter = <0>;
					type = <1>;
					interface = <0>;
					af_2v8-supply = <&ldo10>;
					avdd_2v8-supply = <&ldo11>;
					dovdd_1v8-supply = <&voutsw>;
					dvdd_1v2-supply = <&ldo12>;
					status = "okay";
					sensor_power {
						pinctrl-names = "default";
						pwdn-gpios = <&gpio 80 0>;
						reset-gpios = <&gpio 67 0>;
						pwdn-validvalue = <0>;
						reset-validvalue = <0>;
					};
					sensor_id {
						pid_addr = <0x300a 0x300b>;
						pid_value = <0x88 0x50>;
					};
					torch_flash {
						flash-gpios = <&gpio 18 0>;
						torcht-gpios = <&gpio 12 0>;
					};
				};
				ov8835: sensor@9 {
					compatible = "OVT,ov8835","marvell,sensor";
					sensor-name = "ov8835";
					reg = <0x36>;
					adapter = <0>;
					type = <1>;
					interface = <0>;
					af_2v8-supply = <&ldo10>;
					avdd_2v8-supply = <&ldo11>;
					dovdd_1v8-supply = <&voutsw>;
					dvdd_1v2-supply = <&ldo12>;
					status = "okay";
					sensor_power {
						pinctrl-names = "default";
						pwdn-gpios = <&gpio 80 0>;
						reset-gpios = <&gpio 67 0>;
						pwdn-validvalue = <0>;
						reset-validvalue = <0>;
					};
					sensor_id {
						pid_addr = <0x300a 0x300b>;
						pid_value = <0x88 0x35>;
					};
					torch_flash {
						flash-gpios = <&gpio 18 0>;
						torcht-gpios = <&gpio 12 0>;
					};
				};
				IMX135: sensor@10 {
					compatible = "SONY,imx135","marvell,sensor";
					sensor-name = "imx135";
					reg = <0x10>;
					adapter = <0>;
					type = <1>;
					interface = <0>;
					af_2v8-supply = <&ldo10>;
					avdd_2v8-supply = <&ldo11>;
					dovdd_1v8-supply = <&voutsw>;
					dvdd_1v2-supply = <&ldo12>;
					vcm-subdev = <&dw9714l>;
					status = "okay";
					sensor_power {
						pinctrl-names = "default";
						pwdn-gpios = <&gpio 80 0>;
						reset-gpios = <&gpio 67 0>;
						pwdn-validvalue = <0>;
						reset-validvalue = <0>;
					};
					sensor_id {
						pid_addr = <0x16 0x17>;
						pid_value = <0x01 0x35>;
					};
					torch_flash {
						flash-gpios = <&gpio 18 0>;
						torcht-gpios = <&gpio 12 0>;
					};
				};
				OV5647: sensor@11 {
					compatible = "OVT,ov5647","marvell,sensor";
					sensor-name = "ov5647";
					reg = <0x36>;
					adapter = <0>;
					type = <1>;
					interface = <0>;
					af_2v8-supply = <&ldo10>;
					avdd_2v8-supply = <&ldo11>;
					dovdd_1v8-supply = <&voutsw>;
					dvdd_1v2-supply = <&ldo12>;
					vcm-subdev = <&dw9714l>;
					status = "okay";
					sensor_power {
						pinctrl-names = "default";
						pwdn-gpios = <&gpio 80 0>;
						reset-gpios = <&gpio 67 0>;
						pwdn-validvalue = <0>;
						reset-validvalue = <0>;
					};
					sensor_id {
						pid_addr = <0x300a 0x300b>;
						pid_value = <0x56 0x47>;
					};
					torch_flash {
						flash-gpios = <&gpio 18 0>;
						torcht-gpios = <&gpio 12 0>;
					};
				};
				LSI3H5: sensor@12 {
					compatible = "SSG,lsi3h5","marvell,sensor";
					sensor-name = "lsi3h5";
					reg = <0x10>;
					adapter = <0>;
					type = <1>;
					interface = <0>;
					af_2v8-supply = <&ldo10>;
					avdd_2v8-supply = <&ldo11>;
					dovdd_1v8-supply = <&voutsw>;
					dvdd_1v2-supply = <&ldo12>;
					status = "okay";
					sensor_power {
						pinctrl-names = "default";
						pwdn-gpios = <&gpio 80 0>;
						reset-gpios = <&gpio 67 0>;
						pwdn-validvalue = <0>;
						reset-validvalue = <0>;
					};
					sensor_id {
						pid_addr = <0x0002 0x0003>;
						pid_value = <0xb2 0x01>;
					};
					torch_flash {
						flash-gpios = <&gpio 18 0>;
						torcht-gpios = <&gpio 12 0>;
					};
				};
				S5K4E1: sensor@13 {
					compatible = "SSG,s5k4e1","marvell,sensor";
					sensor-name = "s5k4e1";
					reg = <0x37>;
					adapter = <0>;
					type = <1>;
					interface = <0>;
					af_2v8-supply = <&ldo10>;
					avdd_2v8-supply = <&ldo11>;
					dovdd_1v8-supply = <&voutsw>;
					dvdd_1v2-supply = <&ldo12>;
					status = "okay";
					sensor_power {
						pinctrl-names = "default";
						pwdn-gpios = <&gpio 80 0>;
						reset-gpios = <&gpio 67 0>;
						pwdn-validvalue = <0>;
						reset-validvalue = <0>;
					};
					sensor_id {
						pid_addr = <0x0000 0x0001>;
						pid_value = <0x4e 0x10>;
					};
					torch_flash {
						flash-gpios = <&gpio 18 0>;
						torcht-gpios = <&gpio 12 0>;
					};
				};
				IMX134: sensor@14 {
					compatible = "SONY,imx134","marvell,sensor";
					sensor-name = "imx134";
					reg = <0x37>;
					adapter = <0>;
					type = <1>;
					interface = <0>;
					af_2v8-supply = <&ldo10>;
					avdd_2v8-supply = <&ldo11>;
					dovdd_1v8-supply = <&voutsw>;
					dvdd_1v2-supply = <&ldo12>;
					status = "okay";
					sensor_power {
						pinctrl-names = "default";
						pwdn-gpios = <&gpio 80 0>;
						reset-gpios = <&gpio 67 0>;
						pwdn-validvalue = <0>;
						reset-validvalue = <0>;
					};
					sensor_id {
						pid_addr = <0x0016 0x0017>;
						pid_value = <0x01 0x34>;
					};
					torch_flash {
						flash-gpios = <&gpio 18 0>;
						torcht-gpios = <&gpio 12 0>;
					};
				};
				HI542: sensor@15 {
					compatible = "HNIX,hi542","marvell,sensor";
					sensor-name = "hi542";
					reg = <0x37>;
					adapter = <0>;
					type = <1>;
					interface = <0>;
					af_2v8-supply = <&ldo10>;
					avdd_2v8-supply = <&ldo11>;
					dovdd_1v8-supply = <&voutsw>;
					dvdd_1v2-supply = <&ldo12>;
					status = "okay";
					sensor_power {
						pinctrl-names = "default";
						pwdn-gpios = <&gpio 80 0>;
						reset-gpios = <&gpio 67 0>;
						pwdn-validvalue = <0>;
						reset-validvalue = <0>;
					};
					sensor_id {
						pid_addr = <0x0004>;
						pid_value = <0xb1>;
					};
					torch_flash {
						flash-gpios = <&gpio 18 0>;
						torcht-gpios = <&gpio 12 0>;
					};
				};
				OV8820: sensor@16 {
					compatible = "OVT,ov8820","marvell,sensor";
					sensor-name = "ov8820";
					reg = <0x36>;
					adapter = <0>;
					type = <1>;
					interface = <0>;
					af_2v8-supply = <&ldo10>;
					avdd_2v8-supply = <&ldo11>;
					dovdd_1v8-supply = <&voutsw>;
					dvdd_1v2-supply = <&ldo12>;
					status = "okay";
					sensor_power {
						pinctrl-names = "default";
						pwdn-gpios = <&gpio 80 0>;
						reset-gpios = <&gpio 67 0>;
						pwdn-validvalue = <0>;
						reset-validvalue = <0>;
					};
					sensor_id {
						pid_addr = <0x300a 0x300b>;
						pid_value = <0x88 0x20>;
					};
					torch_flash {
						flash-gpios = <&gpio 18 0>;
						torcht-gpios = <&gpio 12 0>;
					};
				};
				OV12830: sensor@17 {
					compatible = "OVT,ov12830","marvell,sensor";
					sensor-name = "ov12830";
					reg = <0x36>;
					adapter = <0>;
					type = <1>;
					interface = <0>;
					af_2v8-supply = <&ldo10>;
					avdd_2v8-supply = <&ldo11>;
					dovdd_1v8-supply = <&voutsw>;
					dvdd_1v2-supply = <&ldo12>;
					status = "okay";
					sensor_power {
						pinctrl-names = "default";
						pwdn-gpios = <&gpio 80 0>;
						reset-gpios = <&gpio 67 0>;
						pwdn-validvalue = <0>;
						reset-validvalue = <0>;
					};
					sensor_id {
						pid_addr = <0x300a 0x300b>;
						pid_value = <0xc8 0x30>;
					};
					torch_flash {
						flash-gpios = <&gpio 18 0>;
						torcht-gpios = <&gpio 12 0>;
					};
				};

			};
			frontsensor {
				#address-cells = <1>;
				#size-cells = <0>;
				compatible = "marvell,backsensor";
				status = "disable";
			};
			backhost {
				compatible = "marvell,backhost";
				status = "okay";
				flash_led = <&boardflash>;
			};
		};

		soc-camera@0 {
			status = "okay";
		};

		soc-camera@1 {
			status = "okay";
		};
		soc-camera@2 {
			status = "okay";
		};
		soc-camera@3 {
			status = "okay";
		};

		/*
		 * ramoops:
		 * 256 KB memory starts at 0x8100000
		 * pstore dump: 2 chunks, totall 64 KB, 32 KB each
		 * console size: 192 KB
		 * no dump_oops
		 */
		ramoops {
			compatible = "pstore,ramoops";
			mem-size = <0x40000>;
			mem-address = <0x8100000>;
			record-size = <0x8000>;
			console-size = <0x30000>;
			dump-oops = <0>;
			status = "okay";
		};
	};

	sound {
		compatible = "marvell,pxa-88pm805-snd-card";
		ssp-controllers = <&ssp_dai1 &ssp_dai4>;
	};

	ion {
		marvell,ion-nr = <2>;
		status = "okay";
		heap1 {
			marvell,ion-name = "carveout_heap";
			marvell,ion-type = <2>;
			marvell,ion-id = <2>;
			marvell,ion-base = <0>;
			marvell,ion-size = <0>;
		};
		heap2 {
			marvell,ion-name = "system_heap";
			marvell,ion-type = <0>;
			marvell,ion-id = <0>;
		};
	};

	panel1: lg4591 {
		compatible = "marvell,mmp-lg4591";
		marvell,path-name = "mmp_pnpath";
		rst_gpio = <&gpio 4 0>;
		avdd-supply = <&ldo10>;
		status = "okay";
	};

	panel2: r63311 {
		compatible = "marvell,mmp-dsi-panel";
		marvell,path-name = "mmp_pnpath";
		marvell,ddrfreq-qos = <312000>; /* DDR_CONSTRAINT_LVL1 */
		/*
		 * BACKLIGHT CONTROL BY GPIO
		 */
		bl_gpio = <&gpio 32 0>;
		status = "okay";
		/*
		 * DSI PACKET HEADER INFO
		 * @ data type : 1byte
		 * @ command type : 1byte
		 * @ delay(msec) : 2byte
		 * @ size of data : 2byte
		 */
		marvell,dsi-panel-init-cmds = [
			29 00 00 00 00 02	B0 04
			05 00 00 00 00 01	00
			05 00 00 00 00 01	00
			29 00 00 00 00 08	CE 00 01 88 C1 00 1E 04
			29 00 00 00 00 02	D6 01
			15 00 00 00 00 03	51 0F FF
			15 00 00 00 00 02	53 24
		];
		marvell,dsi-panel-enable-cmds = [
			05 00 00 78 00 01	29
			05 00 00 0A 00 01	11
		];
		marvell,dsi-panel-disable-cmds = [
			05 00 00 0A 00 01	28
			05 00 00 78 00 01	10
		];
		video_mode {
			marvell,dsi-panel-xres = <1080>;
			marvell,dsi-panel-yres = <1920>;
			marvell,dsi-panel-width= <62>;      /* screen width in mm */
			marvell,dsi-panel-height = <110>;    /* screen height in mm */
			marvell,dsi-h-front-porch = <132>;   /* right margin */
			marvell,dsi-h-back-porch = <40>;    /* left margin */
			marvell,dsi-h-sync-width = <2>;    /* hsync len */
			marvell,dsi-v-front-porch = <30>;    /* lower margin */
			marvell,dsi-v-back-porch = <2>;    /* upper margin */
			marvell,dsi-v-sync-width = <2>;     /* vsync len */
		};
		panel-ext-pin {
			/*
			 * Three properties are required
			 * to control pwr pin
			 * @node : panel-ext-pin node
			 * @on : <0> - off / <1> - on
			 * @usec : delay time of usec
			 */
			/*
			* panel-ext-pin-boot sequence
			* is skip power on mode
			*/
			panel-ext-pin-boot = <
				&panel_pwr_avdd_2  1 20000
			>;
			panel-ext-pin-on = <
				&panel_pwr_avdd_2  1 20000
				&panel_pwr_rst_2   1 10000
				&panel_pwr_rst_2   0 10000
				&panel_pwr_rst_2   1 120000
			>;
			panel-ext-pin-off = <
				&panel_pwr_avdd_2  0 1000
			>;
			/*
			 * There are four properties to define pwr pin
			 * <prefix>-name : pin name
			 * <prefix>-type : <0> - GPIO, <1> - PMIC Regulator
			 * <prefix>-gpio : If the type is GPIO, assign a gpio.
			 * <prefix>-supply : If the type is PMIC Regulator, assign a regulator.
			 */
			panel_pwr_rst_2: panel-pwr-rst-2 {
				panel-ext-pin-name = "rst";
				panel-ext-pin-type = <0>;
				panel-ext-pin-gpio = <&gpio 4 0>;
			};
			panel_pwr_avdd_2: panel-pwr-avdd-2 {
				panel-ext-pin-name = "avdd";
				panel-ext-pin-type = <0>;
				panel-ext-pin-gpio = <&gpio 6 0>;
			};
		};
	};

	panel4: hx8394 {
		compatible = "marvell,mmp-dsi-panel";
		marvell,path-name = "mmp_pnpath";
		panel_esd = <0>;
		status = "okay";
		/*
		 * DSI PACKET HEADER INFO
		 * @ data type : 1byte
		 * @ command type : 1byte
		 * @ delay(msec) : 2byte
		 * @ size of data : 2byte
		 */
		marvell,dsi-panel-init-cmds = [
			39 01 00 00 00 04	B9 FF 83 94
			39 01 00 00 00 02	BA 13
			39 01 00 00 00 11	B1 01 00 04 87 03 11 11 2A 34 3F 3F 47 02 01 E6
							E2
			39 01 00 00 00 17	B4 80 06 32 10 03 32 15 08 32 10 08 33 04 43 05
							37 04 3F 06 61 61 06
			39 01 00 00 00 07	B2 00 C8 08 04 00 22
			39 01 00 00 00 21	D5 00 00 00 00 0A 00 01 00 CC 00 00 00 88 88 88
							88 88 88 88 88 88 88 01 67 45 23 01 23 88 88 88
							88
			39 01 00 00 00 05	C7 00 10 00 10
			39 01 00 00 00 05	BF 06 00 10 04
			39 01 00 00 00 02	CC 09
			39 01 00 00 00 2B	E0 00 04 06 2B 33 3F 11 34 0A 0E 0D 11 13 11 13
							10 17 00 04 06 2B 33 3F 11 34 0A 0E 0D 11 13 11
							13 10 17 0B 17 07 11 0B 17 07 11
			39 01 00 00 00 80	C1 01 00 07 0E 15 1D 25 2D 34 3C 42 49 51 58 5F
							67 6F 77 80 87 8F 98 9F A7 AF B7 C1 CB D3 DD E6
							EF F6 FF 16 25 7C 62 CA 3A C2 1F C0 00 07 0E 15
							1D 25 2D 34 3C 42 49 51 58 5F 67 6F 77 80 87 8F
							98 9F A7 AF B7 C1 CB D3 DD E6 EF F6 FF 16 25 7C
							62 CA 3A C2 1F C0 00 07 0E 15 1D 25 2D 34 3C 42
							49 51 58 5F 67 6F 77 80 87 8F 98 9F A7 AF B7 C1
							CB D3 DD E6 EF F6 FF 16 25 7C 62 CA 3A C2 1F C0
			39 01 00 00 00 0C	C9 0F 02 1E 1E 00 00 00 01 3E 00 00
			39 01 00 00 00 02	B6 0C
			39 01 00 00 00 02	D4 32
			15 01 00 00 00 02	51 00
			15 01 00 00 00 02	53 24
		];
		marvell,dsi-panel-enable-cmds = [
			05 00 00 78 00 01	11
			05 00 00 0A 00 01	29
		];
		marvell,dsi-panel-disable-cmds = [
			05 00 00 0A 00 01	28
			05 00 00 78 00 01	10
		];
		/*
		 * BACKLIGHT CONTROL BY PANEL
		 */
		marvell,dsi-panel-backlight-set-brightness-cmds = [
			15 00 00 00 00 02	51 8F
		];
		video_mode {
			marvell,dsi-panel-xres = <720>;
			marvell,dsi-panel-yres = <1280>;
			marvell,dsi-panel-width= <62>;      /* screen width in mm */
			marvell,dsi-panel-height = <110>;    /* screen height in mm */
			marvell,dsi-h-front-porch = <136>;   /* right margin */
			marvell,dsi-h-back-porch = <30>;    /* left margin */
			marvell,dsi-h-sync-width = <2>;    /* hsync len */
			marvell,dsi-v-front-porch = <10>;    /* lower margin */
			marvell,dsi-v-back-porch = <8>;    /* upper margin */
			marvell,dsi-v-sync-width = <2>;     /* vsync len */
		};
		panel-ext-pin {
			/*
			 * Three properties are required
			 * to control pwr pin
			 * @node : panel-ext-pin node
			 * @on : <0> - off / <1> - on
			 * @usec : delay time of usec
			 */
			 /*
			 * panel-ext-pin-boot sequence
			 * is skip power on mode
			 */
			panel-ext-pin-boot = <
				&panel_pwr_avdd_4  1 20000
			>;
			panel-ext-pin-on = <
				&panel_pwr_avdd_4  1 20000
				&panel_pwr_rst_4   1 10000
				&panel_pwr_rst_4   0 10000
				&panel_pwr_rst_4   1 120000
			>;
			panel-ext-pin-off = <
				&panel_pwr_avdd_4  0 1000
			>;
			/*
			 * There are four properties to define pwr pin
			 * <prefix>-name : pin name
			 * <prefix>-type : <0> - GPIO, <1> - PMIC Regulator
			 * <prefix>-gpio : If the type is GPIO, assign a gpio.
			 * <prefix>-supply : If the type is PMIC Regulator, assign a regulator.
			 */
			panel_pwr_rst_4: panel-pwr-rst-4 {
				panel-ext-pin-name = "rst";
				panel-ext-pin-type = <0>;
				panel-ext-pin-gpio = <&gpio 4 0>;
			};
			panel_pwr_avdd_4: panel-pwr-avdd-4 {
				panel-ext-pin-name = "avdd";
				panel-ext-pin-type = <1>;
				panel-ext-pin-supply = <&ldo10>;
				panel-ext-pin-gpio;
			};
		};
	};

	sd8x-rfkill {
		sd-host = <&sdh2>;
		pd-gpio = <&gpio 7 0>;
		rst-gpio = <&gpio 71 0>;
		3v3-ldo-gpio = <&gpio 36 0>;
		edge-wakeup-gpio = <&gpio 39 0>;
		status = "okay";
	};

	sd8xxx-wlan {
		drv_mode = <0x5>;
		cfg80211_wext = <0xc>;
		sta_name = "wlan";
		wfd_name = "p2p";
		max_vir_bss = <1>;
		drvdbg = <0x80007>;
		dev_cap_mask = <0xffffcfff>;
		init_cfg = "mrvl/wifi_init_cfg.conf";
		reg_alpha2 = "US";
		p2p_enh = <1>;
	};

	sd8xxx-bt {
		init_cfg = "mrvl/bt_init_cfg.conf";
	};

	gps: mmp-gps {
		compatible = "marvell,mmp-gps";
		marvell,gps-eclk-ctrl;

		vgps-supply = <&ldo13>;

		pinctrl-names = "default", "idle";
		pinctrl-0 = <&gps_pmx_eclk>;
		pinctrl-1 = <&gps_pmx_gpio>;

		ldo-en-gpio = <&gpio 20 0>;
		on-off-gpio = <&gpio 96 0>;
		reset-n-gpio = <&gpio 70 0>;
	};

	touch: vnc {
		compatible = "vnc-ts";
	};

	tzdd {
		status = "okay";
	};

	iml: iml@7ffffe0{
		compatible = "marvell,mmp-iml";
		reg = <0x07ffffe0 0x10>, <0xd403d200 0x10>, <0xd403b038 0x10>;
		interrupts = <0 56 0x4>;
		interrupt-names = "IPC_MSA_DATA";
		dmas = <&pdma0 0xFF 0>;
		dma-names =  "iml-dma";
		status = "okay";
	};

	led-rgb {
		compatible = "marvell,led-rgb";
		pinctrl-names = "default";
		pinctrl-0 = <&led_pmx_func>;
		led_r = <&gpio 127 0>;
		led_g = <&gpio 103 0>;
		led_b = <&gpio 2 0>;
		status = "okay";
	};
};
